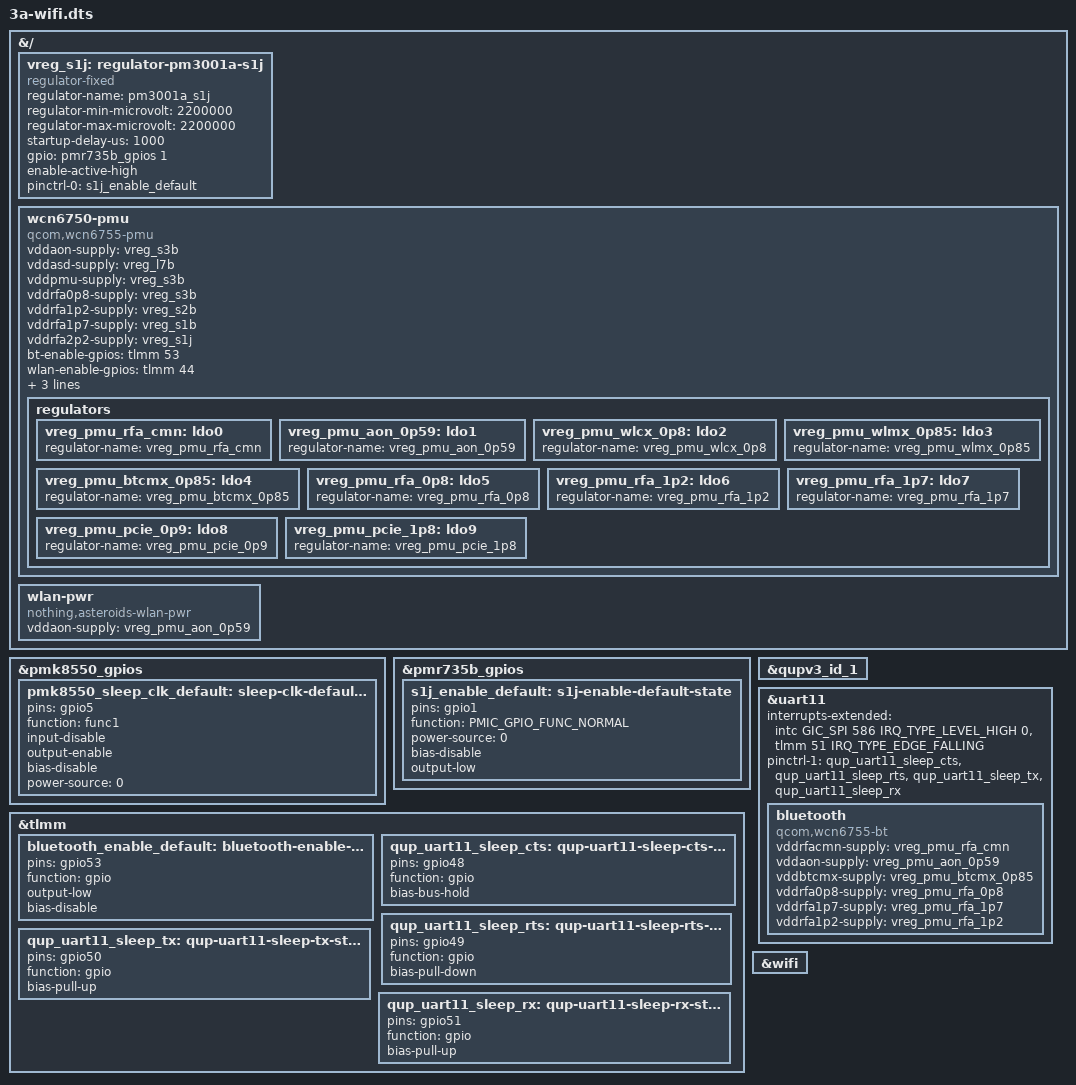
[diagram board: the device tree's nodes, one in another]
// SPDX-License-Identifier: BSD-3-Clause
/*
 * Nothing Phone (3a) Wi-Fi + Bluetooth (WCN6755 RF, MAC in the WPSS), applied at runtime by
 * 3a-ovl-wifi.ko. Wiring from ABL's DTB (same as the Phone (4a) in Nura's DTS):
 *   rails pm7550 S1/S2/S3/L7 + pm3001a S1J (fixed, enabled by PMR735B gpio1), RF_CLK1,
 *   sleep clock on PMK8550 gpio5, BT enable gpio53, BT on uart11 (SE11, gpio48-51).
 * The PMU powers the RF only while a consumer (Bluetooth) holds it: without it the WPSS
 * firmware asserts in whal_wmac_transition_to_fw_control on the first scan.
 */
/dts-v1/;
/plugin/;

#include <dt-bindings/clock/qcom,rpmh.h>
#include <dt-bindings/gpio/gpio.h>
#include <dt-bindings/interrupt-controller/arm-gic.h>
#include <dt-bindings/interrupt-controller/irq.h>
#include <dt-bindings/pinctrl/qcom,pmic-gpio.h>

&{/} {
	vreg_s1j: regulator-pm3001a-s1j {
		compatible = "regulator-fixed";
		regulator-name = "pm3001a_s1j";
		regulator-min-microvolt = <2200000>;
		regulator-max-microvolt = <2200000>;
		startup-delay-us = <1000>;
		gpio = <&pmr735b_gpios 1 GPIO_ACTIVE_HIGH>;
		enable-active-high;
		pinctrl-0 = <&s1j_enable_default>;
		pinctrl-names = "default";
	};

	wcn6750-pmu {
		compatible = "qcom,wcn6755-pmu", "qcom,wcn6750-pmu";

		vddaon-supply = <&vreg_s3b>;
		vddasd-supply = <&vreg_l7b>;
		vddpmu-supply = <&vreg_s3b>;
		vddrfa0p8-supply = <&vreg_s3b>;
		vddrfa1p2-supply = <&vreg_s2b>;
		vddrfa1p7-supply = <&vreg_s1b>;
		vddrfa2p2-supply = <&vreg_s1j>;

		bt-enable-gpios = <&tlmm 53 GPIO_ACTIVE_HIGH>;
		/* ABL: qcom,wl-reset-gpio */
		wlan-enable-gpios = <&tlmm 44 GPIO_ACTIVE_HIGH>;

		clocks = <&rpmhcc RPMH_RF_CLK1>;

		pinctrl-0 = <&bluetooth_enable_default>, <&pmk8550_sleep_clk_default>;
		pinctrl-names = "default";

		regulators {
			vreg_pmu_rfa_cmn: ldo0 {
				regulator-name = "vreg_pmu_rfa_cmn";
			};

			vreg_pmu_aon_0p59: ldo1 {
				regulator-name = "vreg_pmu_aon_0p59";
			};

			vreg_pmu_wlcx_0p8: ldo2 {
				regulator-name = "vreg_pmu_wlcx_0p8";
			};

			vreg_pmu_wlmx_0p85: ldo3 {
				regulator-name = "vreg_pmu_wlmx_0p85";
			};

			vreg_pmu_btcmx_0p85: ldo4 {
				regulator-name = "vreg_pmu_btcmx_0p85";
			};

			vreg_pmu_rfa_0p8: ldo5 {
				regulator-name = "vreg_pmu_rfa_0p8";
			};

			vreg_pmu_rfa_1p2: ldo6 {
				regulator-name = "vreg_pmu_rfa_1p2";
			};

			vreg_pmu_rfa_1p7: ldo7 {
				regulator-name = "vreg_pmu_rfa_1p7";
			};

			vreg_pmu_pcie_0p9: ldo8 {
				regulator-name = "vreg_pmu_pcie_0p9";
			};

			vreg_pmu_pcie_1p8: ldo9 {
				regulator-name = "vreg_pmu_pcie_1p8";
			};
		};
	};

	/* 3a-wlan-pwr.ko: the PMU's "wlan" consumer, so the RF stays up with Bluetooth off */
	wlan-pwr {
		compatible = "nothing,asteroids-wlan-pwr";
		vddaon-supply = <&vreg_pmu_aon_0p59>;
	};
};

&pmk8550_gpios {
	pmk8550_sleep_clk_default: sleep-clk-default-state {
		pins = "gpio5";
		function = "func1";
		input-disable;
		output-enable;
		bias-disable;
		power-source = <0>;
	};
};

&pmr735b_gpios {
	s1j_enable_default: s1j-enable-default-state {
		pins = "gpio1";
		function = PMIC_GPIO_FUNC_NORMAL;
		power-source = <0>;
		bias-disable;
		output-low;
	};
};

&tlmm {
	bluetooth_enable_default: bluetooth-enable-default-state {
		pins = "gpio53";
		function = "gpio";
		output-low;
		bias-disable;
	};

	qup_uart11_sleep_cts: qup-uart11-sleep-cts-state {
		pins = "gpio48";
		function = "gpio";
		bias-bus-hold;
	};

	qup_uart11_sleep_rts: qup-uart11-sleep-rts-state {
		pins = "gpio49";
		function = "gpio";
		bias-pull-down;
	};

	qup_uart11_sleep_tx: qup-uart11-sleep-tx-state {
		pins = "gpio50";
		function = "gpio";
		bias-pull-up;
	};

	qup_uart11_sleep_rx: qup-uart11-sleep-rx-state {
		pins = "gpio51";
		function = "gpio";
		bias-pull-up;
	};
};

&qupv3_id_1 {
	status = "okay";
};

&uart11 {
	/delete-property/ interrupts;
	interrupts-extended = <&intc GIC_SPI 586 IRQ_TYPE_LEVEL_HIGH 0>,
			      <&tlmm 51 IRQ_TYPE_EDGE_FALLING>;

	pinctrl-1 = <&qup_uart11_sleep_cts>,
		    <&qup_uart11_sleep_rts>,
		    <&qup_uart11_sleep_tx>,
		    <&qup_uart11_sleep_rx>;
	pinctrl-names = "default", "sleep";

	status = "okay";

	bluetooth {
		compatible = "qcom,wcn6755-bt", "qcom,wcn6750-bt";

		vddrfacmn-supply = <&vreg_pmu_rfa_cmn>;
		vddaon-supply = <&vreg_pmu_aon_0p59>;
		vddbtcmx-supply = <&vreg_pmu_btcmx_0p85>;
		vddrfa0p8-supply = <&vreg_pmu_rfa_0p8>;
		vddrfa1p7-supply = <&vreg_pmu_rfa_1p7>;
		vddrfa1p2-supply = <&vreg_pmu_rfa_1p2>;
	};
};

&wifi {
	status = "okay";
};
